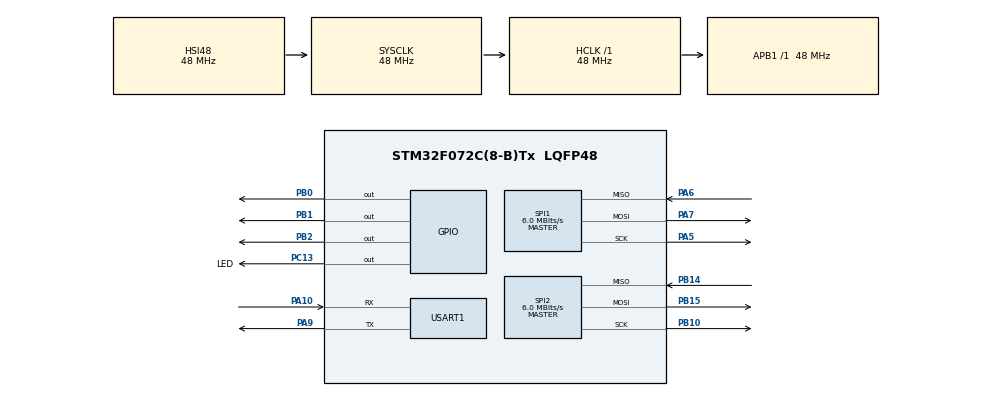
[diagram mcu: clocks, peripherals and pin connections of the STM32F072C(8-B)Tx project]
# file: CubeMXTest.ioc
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Mcu.Family=STM32F0
Mcu.Name=STM32F072C(8-B)Tx
Mcu.Package=LQFP48
PA10.Mode=Asynchronous
PA10.Signal=USART1_RX
PA13.Mode=Serial_Wire
PA13.Signal=SYS_SWDIO
PA14.Mode=Serial_Wire
PA14.Signal=SYS_SWCLK
PA5.Mode=Full_Duplex_Master
PA5.Signal=SPI1_SCK
PA6.Mode=Full_Duplex_Master
PA6.Signal=SPI1_MISO
PA7.Mode=Full_Duplex_Master
PA7.Signal=SPI1_MOSI
PA8.Signal=S_TIM1_CH1
PA9.Mode=Asynchronous
PA9.Signal=USART1_TX
PB0.Signal=GPIO_Output
PB1.GPIO_PuPd=GPIO_NOPULL
PB1.PinState=GPIO_PIN_SET
PB1.Signal=GPIO_Output
PB10.Mode=Full_Duplex_Master
PB10.Signal=SPI2_SCK
PB14.Mode=Full_Duplex_Master
PB14.Signal=SPI2_MISO
PB15.Mode=Full_Duplex_Master
PB15.Signal=SPI2_MOSI
PB2.PinState=GPIO_PIN_SET
PB2.Signal=GPIO_Output
PC13.GPIO_Label=LED
PC13.GPIO_PuPd=GPIO_NOPULL
PC13.Signal=GPIO_Output
ProjectManager.HeapSize=0x200
ProjectManager.StackSize=0x400
ProjectManager.TargetToolchain=Makefile
RCC.AHBFreq_Value=48000000
RCC.APB1Freq_Value=48000000
RCC.APB1TimFreq_Value=48000000
RCC.HCLKFreq_Value=48000000
RCC.SYSCLKFreq_VALUE=48000000
RCC.SYSCLKSource=RCC_SYSCLKSOURCE_HSI48
SH.S_TIM1_CH1.0=TIM1_CH1
SPI1.BaudRatePrescaler=SPI_BAUDRATEPRESCALER_8
SPI1.CalculateBaudRate=6.0 MBits/s
SPI1.DataSize=SPI_DATASIZE_8BIT
SPI1.Direction=SPI_DIRECTION_2LINES
SPI1.Mode=SPI_MODE_MASTER
SPI1.VirtualType=VM_MASTER
SPI2.BaudRatePrescaler=SPI_BAUDRATEPRESCALER_8
SPI2.CalculateBaudRate=6.0 MBits/s
SPI2.Direction=SPI_DIRECTION_2LINES
SPI2.Mode=SPI_MODE_MASTER
SPI2.VirtualType=VM_MASTER
USART1.VirtualMode-Asynchronous=VM_ASYNC
board=custom

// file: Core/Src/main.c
/* USER CODE BEGIN Header */
/**
  ******************************************************************************
  * @file           : main.c
  * @brief          : Main program body
  ******************************************************************************
  * @attention
  *
  * Copyright (c) 2025 STMicroelectronics.
  * All rights reserved.
  *
  * This software is licensed under terms that can be found in the LICENSE file
  * in the root directory of this software component.
  * If no LICENSE file comes with this software, it is provided AS-IS.
  *
  ******************************************************************************
  */
/* USER CODE END Header */
#include "main.h"

SPI_HandleTypeDef hspi1;
SPI_HandleTypeDef hspi2;

UART_HandleTypeDef huart1;

void SystemClock_Config(void);
static void MX_GPIO_Init(void);
static void MX_SPI1_Init(void);
static void MX_SPI2_Init(void);
static void MX_USART1_UART_Init(void);

int main(void)
{

  /* MCU Configuration--------------------------------------------------------*/

  /* Reset of all peripherals, Initializes the Flash interface and the Systick. */
  HAL_Init();

  /* Configure the system clock */
  SystemClock_Config();

  /* Initialize all configured peripherals */
  MX_GPIO_Init();
  MX_SPI1_Init();
  MX_SPI2_Init();
  MX_USART1_UART_Init();
  /* USER CODE BEGIN 2 */
  HAL_GPIO_WritePin(LED_GPIO_Port, LED_Pin, GPIO_PIN_SET);

    HAL_Delay(500);

     //uint8_t dummy = 0xFF;
     uint8_t first_cmd = 0x40;
     //uint8_t second_cmd = 0x00;
     //uint8_t last_cmd = 0x95;
     // uint8_t cmd1[6] = {0x40, 0x00, 0x00, 0x00, 0x00, 0x95};

     //uint8_t result;
     //HAL_GPIO_WritePin(GPIOB, GPIO_PIN_0, GPIO_PIN_SET);

    //for(int i = 0; i < 19; i++) {
      //HAL_SPI_Transmit(&hspi2, &dummy, 1, HAL_MAX_DELAY);
     //}

     HAL_GPIO_WritePin(GPIOB, GPIO_PIN_0, GPIO_PIN_RESET);
     //do{

      HAL_SPI_Transmit(&hspi2, &first_cmd, 1, HAL_MAX_DELAY);
      // for(int i = 0; i <= 3; i++) {
        // HAL_SPI_Transmit(&hspi2, &second_cmd, 1, HAL_MAX_DELAY);
      // }
      // HAL_SPI_Transmit(&hspi2, &last_cmd, 1, HAL_MAX_DELAY);

      HAL_GPIO_WritePin(GPIOB, GPIO_PIN_0, GPIO_PIN_SET);
     //} while(result != 0x01);

  /* USER CODE END 2 */

  /* Infinite loop */
  while (1)
  {

  }
}

void SystemClock_Config(void)
{
  RCC_OscInitTypeDef RCC_OscInitStruct = {0};
  RCC_ClkInitTypeDef RCC_ClkInitStruct = {0};
  RCC_PeriphCLKInitTypeDef PeriphClkInit = {0};

  /** Initializes the RCC Oscillators according to the specified parameters
  * in the RCC_OscInitTypeDef structure.
  */
  RCC_OscInitStruct.OscillatorType = RCC_OSCILLATORTYPE_HSI48;
  RCC_OscInitStruct.HSI48State = RCC_HSI48_ON;
  RCC_OscInitStruct.PLL.PLLState = RCC_PLL_NONE;
  if (HAL_RCC_OscConfig(&RCC_OscInitStruct) != HAL_OK)
  {
    Error_Handler();
  }

  /** Initializes the CPU, AHB and APB buses clocks
  */
  RCC_ClkInitStruct.ClockType = RCC_CLOCKTYPE_HCLK|RCC_CLOCKTYPE_SYSCLK
                              |RCC_CLOCKTYPE_PCLK1;
  RCC_ClkInitStruct.SYSCLKSource = RCC_SYSCLKSOURCE_HSI48;
  RCC_ClkInitStruct.AHBCLKDivider = RCC_SYSCLK_DIV1;
  RCC_ClkInitStruct.APB1CLKDivider = RCC_HCLK_DIV1;

  if (HAL_RCC_ClockConfig(&RCC_ClkInitStruct, FLASH_LATENCY_1) != HAL_OK)
  {
    Error_Handler();
  }
  PeriphClkInit.PeriphClockSelection = RCC_PERIPHCLK_USART1;
  PeriphClkInit.Usart1ClockSelection = RCC_USART1CLKSOURCE_PCLK1;
  if (HAL_RCCEx_PeriphCLKConfig(&PeriphClkInit) != HAL_OK)
  {
    Error_Handler();
  }
}

static void MX_SPI1_Init(void)
{

  /* SPI1 parameter configuration*/
  hspi1.Instance = SPI1;
  hspi1.Init.Mode = SPI_MODE_MASTER;
  hspi1.Init.Direction = SPI_DIRECTION_2LINES;
  hspi1.Init.DataSize = SPI_DATASIZE_8BIT;
  hspi1.Init.CLKPolarity = SPI_POLARITY_LOW;
  hspi1.Init.CLKPhase = SPI_PHASE_1EDGE;
  hspi1.Init.NSS = SPI_NSS_SOFT;
  hspi1.Init.BaudRatePrescaler = SPI_BAUDRATEPRESCALER_8;
  hspi1.Init.FirstBit = SPI_FIRSTBIT_MSB;
  hspi1.Init.TIMode = SPI_TIMODE_DISABLE;
  hspi1.Init.CRCCalculation = SPI_CRCCALCULATION_DISABLE;
  hspi1.Init.CRCPolynomial = 7;
  hspi1.Init.CRCLength = SPI_CRC_LENGTH_DATASIZE;
  hspi1.Init.NSSPMode = SPI_NSS_PULSE_ENABLE;
  if (HAL_SPI_Init(&hspi1) != HAL_OK)
  {
    Error_Handler();
  }

}

static void MX_SPI2_Init(void)
{

  /* SPI2 parameter configuration*/
  hspi2.Instance = SPI2;
  hspi2.Init.Mode = SPI_MODE_MASTER;
  hspi2.Init.Direction = SPI_DIRECTION_2LINES;
  hspi2.Init.DataSize = SPI_DATASIZE_4BIT;
  hspi2.Init.CLKPolarity = SPI_POLARITY_LOW;
  hspi2.Init.CLKPhase = SPI_PHASE_1EDGE;
  hspi2.Init.NSS = SPI_NSS_SOFT;
  hspi2.Init.BaudRatePrescaler = SPI_BAUDRATEPRESCALER_8;
  hspi2.Init.FirstBit = SPI_FIRSTBIT_MSB;
  hspi2.Init.TIMode = SPI_TIMODE_DISABLE;
  hspi2.Init.CRCCalculation = SPI_CRCCALCULATION_DISABLE;
  hspi2.Init.CRCPolynomial = 7;
  hspi2.Init.CRCLength = SPI_CRC_LENGTH_DATASIZE;
  hspi2.Init.NSSPMode = SPI_NSS_PULSE_ENABLE;
  if (HAL_SPI_Init(&hspi2) != HAL_OK)
  {
    Error_Handler();
  }

}

static void MX_USART1_UART_Init(void)
{

  huart1.Instance = USART1;
  huart1.Init.BaudRate = 38400;
  huart1.Init.WordLength = UART_WORDLENGTH_8B;
  huart1.Init.StopBits = UART_STOPBITS_1;
  huart1.Init.Parity = UART_PARITY_NONE;
  huart1.Init.Mode = UART_MODE_TX_RX;
  huart1.Init.HwFlowCtl = UART_HWCONTROL_NONE;
  huart1.Init.OverSampling = UART_OVERSAMPLING_16;
  huart1.Init.OneBitSampling = UART_ONE_BIT_SAMPLE_DISABLE;
  huart1.AdvancedInit.AdvFeatureInit = UART_ADVFEATURE_NO_INIT;
  if (HAL_UART_Init(&huart1) != HAL_OK)
  {
    Error_Handler();
  }

}

static void MX_GPIO_Init(void)
{
  GPIO_InitTypeDef GPIO_InitStruct = {0};

  /* GPIO Ports Clock Enable */
  __HAL_RCC_GPIOC_CLK_ENABLE();
  __HAL_RCC_GPIOA_CLK_ENABLE();
  __HAL_RCC_GPIOB_CLK_ENABLE();

  /*Configure GPIO pin Output Level */
  HAL_GPIO_WritePin(LED_GPIO_Port, LED_Pin, GPIO_PIN_RESET);

  /*Configure GPIO pin Output Level */
  HAL_GPIO_WritePin(GPIOB, GPIO_PIN_0, GPIO_PIN_RESET);

  /*Configure GPIO pin Output Level */
  HAL_GPIO_WritePin(GPIOB, GPIO_PIN_1|GPIO_PIN_2, GPIO_PIN_SET);

  /*Configure GPIO pin : LED_Pin */
  GPIO_InitStruct.Pin = LED_Pin;
  GPIO_InitStruct.Mode = GPIO_MODE_OUTPUT_PP;
  GPIO_InitStruct.Pull = GPIO_NOPULL;
  GPIO_InitStruct.Speed = GPIO_SPEED_FREQ_LOW;
  HAL_GPIO_Init(LED_GPIO_Port, &GPIO_InitStruct);

  /*Configure GPIO pins : PB0 PB1 PB2 */
  GPIO_InitStruct.Pin = GPIO_PIN_0|GPIO_PIN_1|GPIO_PIN_2;
  GPIO_InitStruct.Mode = GPIO_MODE_OUTPUT_PP;
  GPIO_InitStruct.Pull = GPIO_NOPULL;
  GPIO_InitStruct.Speed = GPIO_SPEED_FREQ_LOW;
  HAL_GPIO_Init(GPIOB, &GPIO_InitStruct);

  /*Configure GPIO pin : PA8 */
  GPIO_InitStruct.Pin = GPIO_PIN_8;
  GPIO_InitStruct.Mode = GPIO_MODE_AF_PP;
  GPIO_InitStruct.Pull = GPIO_NOPULL;
  GPIO_InitStruct.Speed = GPIO_SPEED_FREQ_LOW;
  GPIO_InitStruct.Alternate = GPIO_AF2_TIM1;
  HAL_GPIO_Init(GPIOA, &GPIO_InitStruct);

}

void Error_Handler(void)
{
  __disable_irq();
  while (1)
  {
  }
}
